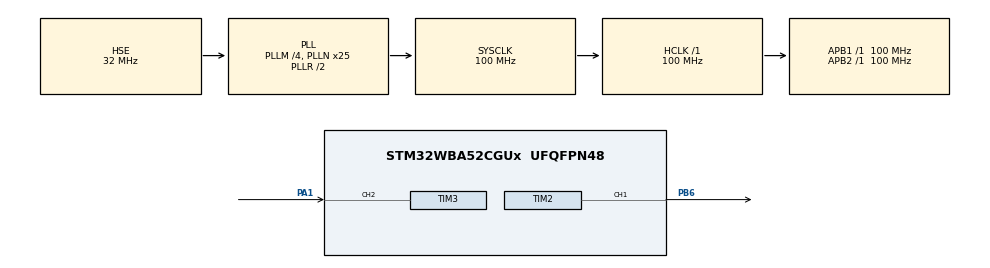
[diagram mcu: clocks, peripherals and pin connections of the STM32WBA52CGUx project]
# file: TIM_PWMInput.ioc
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CORTEX_M33_NS.userName=CORTEX_M33
Mcu.Family=STM32WBA
Mcu.Name=STM32WBA52CGUx
Mcu.Package=UFQFPN48
NVIC.PriorityGroup=NVIC_PRIORITYGROUP_4
OSC_IN.Mode=HSE-External-Oscillator
OSC_IN.Signal=RCC_OSC_IN
OSC_OUT.Mode=HSE-External-Oscillator
OSC_OUT.Signal=RCC_OSC_OUT
PA1.Signal=S_TIM3_CH2
PB6.Signal=S_TIM2_CH1
ProjectManager.HeapSize=0x200
ProjectManager.StackSize=0x400
ProjectManager.TargetToolchain=EWARM V9.20
RCC.ADCFreq_Value=100000000
RCC.AHB5CLKDivider=DIV4
RCC.AHBFreq_Value=100000000
RCC.APB1Freq_Value=100000000
RCC.APB1TimFreq_Value=100000000
RCC.APB2Freq_Value=100000000
RCC.APB2TimFreq_Value=100000000
RCC.CortexFreq_Value=100000000
RCC.HCLKFreq_Value=100000000
RCC.HSE_VALUE=32000000
RCC.HSI_VALUE=16000000
RCC.LSE_VALUE=32768
RCC.PLLFRACN=0
RCC.PLLM=4
RCC.PLLN=25
RCC.PLLSourceVirtual=RCC_PLLSOURCE_HSE
RCC.SYSCLKFreq_VALUE=100000000
RCC.SYSCLKSourceVirtual=RCC_SYSCLKSOURCE_PLLCLK
RCC.VCOOutputFreq_Value=200000000
SH.S_TIM2_CH1.0=TIM2_CH1,PWM Generation1 CH1
SH.S_TIM3_CH2.0=TIM3_CH2,Input_Capture2_from_TI2
SH.S_TIM3_CH2.1=TIM3_CH2,TriggerSource_TI2FP2
SH.S_TIM3_CH2.2=TIM3_CH2,Input_Capture1_from_TI2
TIM2.AutoReloadPreload=TIM_AUTORELOAD_PRELOAD_DISABLE
TIM2.Channel-PWM\ Generation1\ CH1=TIM_CHANNEL_1
TIM2.ClearInputSource=TIM_CLEARINPUTSOURCE_NONE
TIM2.ClockDivision=TIM_CLOCKDIVISION_DIV1
TIM2.CounterMode=TIM_COUNTERMODE_UP
TIM2.OC1Preload_PWM=ENABLE
TIM2.OCFastMode_PWM-PWM\ Generation1\ CH1=TIM_OCFAST_DISABLE
TIM2.OCMode_PWM-PWM\ Generation1\ CH1=TIM_OCMODE_PWM1
TIM2.OCPolarity_1=TIM_OCPOLARITY_HIGH
TIM2.Period=(SystemCoreClock/1)/aFrequency[0]
TIM2.Prescaler=uhPrescalerValue
TIM2.TIM_MasterOutputTrigger=TIM_TRGO_RESET
TIM2.TIM_MasterSlaveMode=TIM_MASTERSLAVEMODE_DISABLE
TIM3.AutoReloadPreload=TIM_AUTORELOAD_PRELOAD_DISABLE
TIM3.Channel-Input_Capture1_from_TI2=TIM_CHANNEL_1
TIM3.Channel-Input_Capture2_from_TI2=TIM_CHANNEL_2
TIM3.ClockDivision=TIM_CLOCKDIVISION_DIV1
TIM3.CounterMode=TIM_COUNTERMODE_UP
TIM3.ICFilter_CH2=0
TIM3.ICPolarity_CH1=TIM_INPUTCHANNELPOLARITY_FALLING
TIM3.ICPolarity_CH2=TIM_INPUTCHANNELPOLARITY_RISING
TIM3.ICPrescaler-Input_Capture1_from_TI2=TIM_ICPSC_DIV1
TIM3.ICPrescaler-Input_Capture2_from_TI2=TIM_ICPSC_DIV1
TIM3.ICSelection-Input_Capture1_from_TI2=TIM_ICSELECTION_INDIRECTTI
TIM3.ICSelection-Input_Capture2_from_TI2=TIM_ICSELECTION_DIRECTTI
TIM3.Period=0xFFFF
TIM3.Prescaler=0x0
TIM3.TIM_MasterOutputTrigger=TIM_TRGO_RESET
TIM3.TIM_MasterSlaveMode=TIM_MASTERSLAVEMODE_DISABLE
TIM3.TIM_SlaveMode=TIM_SLAVEMODE_RESET
VP_ICACHE_VS_ICACHE.Mode=DirectMappedCache
VP_PWR_VS_SECSignals.Mode=Security/Privilege
VP_TIM3_VS_ControllerModeReset.Mode=Reset Mode
board=custom

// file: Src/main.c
/* USER CODE BEGIN Header */
/**
  ******************************************************************************
  * @file    TIM/TIM_PWMInput/Src/main.c
  * @author  MCD Application Team
  * @brief   This example shows how to use the TIM peripheral to measure the
  *          frequency and duty cycle of an external signal.
  ******************************************************************************
  * @attention
  *
  * Copyright (c) 2022 STMicroelectronics.
  * All rights reserved.
  *
  * This software is licensed under terms that can be found in the LICENSE file
  * in the root directory of this software component.
  * If no LICENSE file comes with this software, it is provided AS-IS.
  *
  ******************************************************************************
  */
/* USER CODE END Header */
#include "main.h"

/* USER CODE BEGIN PD */
/* Number of frequencies */
#define TIM_FREQUENCIES_NB 6
#define TIM_DUTYCYCLE_NB 2
/* USER CODE END PD */

TIM_HandleTypeDef htim2;
TIM_HandleTypeDef htim3;

/* USER CODE BEGIN PV */

/* Captured Value */
__IO uint32_t            uwIC2Value = 0;
/* Duty Cycle Value */
__IO uint32_t            uwDutyCycle = 0;
/* Frequency Value */
__IO uint32_t            uwFrequency = 0;

/* Counter Prescaler value */
uint32_t uhPrescalerValue = 0;

static uint8_t iFrequency = 0;
/* Frequency index *//* Frequency table */
static uint32_t aFrequency[TIM_FREQUENCIES_NB] = {
  2000,   /*  2 kHz */
  2000,   /*  2 kHz */
  3000,   /*  3 kHz */
  3000,   /*  3 kHz */
  4000,   /*  4 kHz */
  4000,   /*  4 kHz */
};
/* Frequency index */

static uint8_t iDutyCycle = 0;
static uint32_t aDutyCycle[TIM_DUTYCYCLE_NB] = {
  2,   /*  50% */
  4,   /*  25% */
};

/* USER CODE END PV */

void SystemClock_Config(void);
static void MX_GPIO_Init(void);
static void MX_TIM3_Init(void);
static void MX_ICACHE_Init(void);
static void MX_TIM2_Init(void);

int main(void)
{
  /* USER CODE BEGIN 1 */

  /* STM32WBAxx HAL library initialization:
       - Systick timer is configured by default as source of time base, but user
             can eventually implement his proper time base source (a general purpose
             timer for example or other time source), keeping in mind that Time base
             duration should be kept 1ms since PPP_TIMEOUT_VALUEs are defined and
             handled in milliseconds basis.
       - Set NVIC Group Priority to 4
       - Low Level Initialization
     */

  /* USER CODE END 1 */

  /* MCU Configuration--------------------------------------------------------*/

  /* Reset of all peripherals, Initializes the Flash interface and the Systick. */
  HAL_Init();

  /* Configure the system clock */
  SystemClock_Config();

  /* USER CODE BEGIN SysInit */

  /* Configure LD3 */
  BSP_LED_Init(LD3);

  /* Configure User push-button in Interrupt mode */
  BSP_PB_Init(B1, BUTTON_MODE_EXTI);

  /* USER CODE END SysInit */

  /* Initialize all configured peripherals */
  MX_GPIO_Init();
  MX_TIM3_Init();
  MX_ICACHE_Init();
  MX_TIM2_Init();
  /* USER CODE BEGIN 2 */

 /* Start Input waveform generation */
  if (HAL_TIM_PWM_Start(&htim2, TIM_CHANNEL_1) != HAL_OK)
  {
    /* PWM Generation Error */
    Error_Handler();
  }

  /* Start the Input Capture in interrupt mode  */
  if (HAL_TIM_IC_Start_IT(&htim3, TIM_CHANNEL_2) != HAL_OK)
  {
    /* Starting Error */
    Error_Handler();
  }

  if (HAL_TIM_IC_Start_IT(&htim3, TIM_CHANNEL_1) != HAL_OK)
  {
    /* Starting Error */
    Error_Handler();
  }

  /* USER CODE END 2 */

  /* Infinite loop */
  while (1)
  {

  }
}

void SystemClock_Config(void)
{
  RCC_OscInitTypeDef RCC_OscInitStruct = {0};
  RCC_ClkInitTypeDef RCC_ClkInitStruct = {0};

  /** Configure the main internal regulator output voltage
  */
  if (HAL_PWREx_ControlVoltageScaling(PWR_REGULATOR_VOLTAGE_SCALE1) != HAL_OK)
  {
    Error_Handler();
  }

  /** Initializes the CPU, AHB and APB busses clocks
  */
  RCC_OscInitStruct.OscillatorType = RCC_OSCILLATORTYPE_HSE;
  RCC_OscInitStruct.HSEState = RCC_HSE_ON;
  RCC_OscInitStruct.HSEDiv = RCC_HSE_DIV1;
  RCC_OscInitStruct.PLL1.PLLState = RCC_PLL_ON;
  RCC_OscInitStruct.PLL1.PLLSource = RCC_PLLSOURCE_HSE;
  RCC_OscInitStruct.PLL1.PLLM = 4;
  RCC_OscInitStruct.PLL1.PLLN = 25;
  RCC_OscInitStruct.PLL1.PLLP = 2;
  RCC_OscInitStruct.PLL1.PLLQ = 2;
  RCC_OscInitStruct.PLL1.PLLR = 2;
  RCC_OscInitStruct.PLL1.PLLFractional = 0;
  if (HAL_RCC_OscConfig(&RCC_OscInitStruct) != HAL_OK)
  {
    Error_Handler();
  }

  /** Initializes the CPU, AHB and APB busses clocks
  */
  RCC_ClkInitStruct.ClockType = RCC_CLOCKTYPE_HCLK|RCC_CLOCKTYPE_SYSCLK
                              |RCC_CLOCKTYPE_PCLK1|RCC_CLOCKTYPE_PCLK2
                              |RCC_CLOCKTYPE_PCLK7|RCC_CLOCKTYPE_HCLK5;
  RCC_ClkInitStruct.SYSCLKSource = RCC_SYSCLKSOURCE_PLLCLK;
  RCC_ClkInitStruct.AHBCLKDivider = RCC_SYSCLK_DIV1;
  RCC_ClkInitStruct.APB1CLKDivider = RCC_HCLK_DIV1;
  RCC_ClkInitStruct.APB2CLKDivider = RCC_HCLK_DIV1;
  RCC_ClkInitStruct.APB7CLKDivider = RCC_HCLK_DIV1;
  RCC_ClkInitStruct.AHB5_PLL1_CLKDivider = RCC_SYSCLK_PLL1_DIV4;
  RCC_ClkInitStruct.AHB5_HSEHSI_CLKDivider = RCC_SYSCLK_HSEHSI_DIV1;

  if (HAL_RCC_ClockConfig(&RCC_ClkInitStruct, FLASH_LATENCY_3) != HAL_OK)
  {
    Error_Handler();
  }
}

static void MX_ICACHE_Init(void)
{

  /** Enable instruction cache in 1-way (direct mapped cache)
  */
  if (HAL_ICACHE_ConfigAssociativityMode(ICACHE_1WAY) != HAL_OK)
  {
    Error_Handler();
  }
  if (HAL_ICACHE_Enable() != HAL_OK)
  {
    Error_Handler();
  }

}

static void MX_TIM2_Init(void)
{

  TIM_MasterConfigTypeDef sMasterConfig = {0};
  TIM_OC_InitTypeDef sConfigOC = {0};

  htim2.Instance = TIM2;
  htim2.Init.Prescaler = uhPrescalerValue;
  htim2.Init.CounterMode = TIM_COUNTERMODE_UP;
  htim2.Init.Period = (SystemCoreClock/1)/aFrequency[0];
  htim2.Init.ClockDivision = TIM_CLOCKDIVISION_DIV1;
  htim2.Init.AutoReloadPreload = TIM_AUTORELOAD_PRELOAD_DISABLE;
  if (HAL_TIM_PWM_Init(&htim2) != HAL_OK)
  {
    Error_Handler();
  }
  sMasterConfig.MasterOutputTrigger = TIM_TRGO_RESET;
  sMasterConfig.MasterSlaveMode = TIM_MASTERSLAVEMODE_DISABLE;
  if (HAL_TIMEx_MasterConfigSynchronization(&htim2, &sMasterConfig) != HAL_OK)
  {
    Error_Handler();
  }
  sConfigOC.OCMode = TIM_OCMODE_PWM1;
  sConfigOC.Pulse = 0;
  sConfigOC.OCPolarity = TIM_OCPOLARITY_HIGH;
  sConfigOC.OCFastMode = TIM_OCFAST_DISABLE;
  if (HAL_TIM_PWM_ConfigChannel(&htim2, &sConfigOC, TIM_CHANNEL_1) != HAL_OK)
  {
    Error_Handler();
  }
  HAL_TIM_MspPostInit(&htim2);

}

static void MX_TIM3_Init(void)
{

  TIM_SlaveConfigTypeDef sSlaveConfig = {0};
  TIM_MasterConfigTypeDef sMasterConfig = {0};
  TIM_IC_InitTypeDef sConfigIC = {0};

  htim3.Instance = TIM3;
  htim3.Init.Prescaler = 0x0;
  htim3.Init.CounterMode = TIM_COUNTERMODE_UP;
  htim3.Init.Period = 0xFFFF;
  htim3.Init.ClockDivision = TIM_CLOCKDIVISION_DIV1;
  htim3.Init.AutoReloadPreload = TIM_AUTORELOAD_PRELOAD_DISABLE;
  if (HAL_TIM_Base_Init(&htim3) != HAL_OK)
  {
    Error_Handler();
  }
  if (HAL_TIM_IC_Init(&htim3) != HAL_OK)
  {
    Error_Handler();
  }
  sSlaveConfig.SlaveMode = TIM_SLAVEMODE_RESET;
  sSlaveConfig.InputTrigger = TIM_TS_TI2FP2;
  sSlaveConfig.TriggerPolarity = TIM_INPUTCHANNELPOLARITY_RISING;
  sSlaveConfig.TriggerFilter = 0;
  if (HAL_TIM_SlaveConfigSynchro(&htim3, &sSlaveConfig) != HAL_OK)
  {
    Error_Handler();
  }
  sMasterConfig.MasterOutputTrigger = TIM_TRGO_RESET;
  sMasterConfig.MasterSlaveMode = TIM_MASTERSLAVEMODE_DISABLE;
  if (HAL_TIMEx_MasterConfigSynchronization(&htim3, &sMasterConfig) != HAL_OK)
  {
    Error_Handler();
  }
  sConfigIC.ICPolarity = TIM_INPUTCHANNELPOLARITY_FALLING;
  sConfigIC.ICSelection = TIM_ICSELECTION_INDIRECTTI;
  sConfigIC.ICPrescaler = TIM_ICPSC_DIV1;
  sConfigIC.ICFilter = 0;
  if (HAL_TIM_IC_ConfigChannel(&htim3, &sConfigIC, TIM_CHANNEL_1) != HAL_OK)
  {
    Error_Handler();
  }
  sConfigIC.ICPolarity = TIM_INPUTCHANNELPOLARITY_RISING;
  sConfigIC.ICSelection = TIM_ICSELECTION_DIRECTTI;
  if (HAL_TIM_IC_ConfigChannel(&htim3, &sConfigIC, TIM_CHANNEL_2) != HAL_OK)
  {
    Error_Handler();
  }

}

static void MX_GPIO_Init(void)
{

  /* GPIO Ports Clock Enable */
  __HAL_RCC_GPIOA_CLK_ENABLE();
  __HAL_RCC_GPIOB_CLK_ENABLE();

}

/* USER CODE BEGIN 4 */

/**
  * @brief EXTI line detection callbacks
  * @param GPIO_Pin: Specifies the pins connected EXTI line
  * @retval None
  */
void UserButton_Callback()
{
    /* Set new PWM signal frequency and duty cycle*/
    iFrequency = (iFrequency + 1) % TIM_FREQUENCIES_NB;
    iDutyCycle = (iDutyCycle + 1) % TIM_DUTYCYCLE_NB;

    /* Set the auto-reload value to have the requested frequency */
    /* Frequency = TIM2CLK / (ARR + 1) = SystemCoreClock / (ARR + 1)  */
    LL_TIM_SetAutoReload(TIM2, __LL_TIM_CALC_ARR(SystemCoreClock/1, LL_TIM_GetPrescaler(TIM2), aFrequency[iFrequency]));

    /* Set  duty cycle */
    LL_TIM_OC_SetCompareCH1(TIM2, (LL_TIM_GetAutoReload(TIM2) / aDutyCycle[iDutyCycle]));

}

/**
  * @brief  Input Capture callback in non blocking mode
  * @param  htim : TIM IC handle
  * @retval None
  */
void TimerCaptureCompare_Ch2_Callback()
{
  /* Get the Input Capture value */
  uwIC2Value = LL_TIM_IC_GetCaptureCH2(TIM3);

  if (uwIC2Value != 0)
  {
    /* Duty cycle computation */
    uwDutyCycle = (LL_TIM_IC_GetCaptureCH1(TIM3) * 100) / uwIC2Value;

    /* uwFrequency computation
    TIM3 freq  = SystemCoreClock */
    uwFrequency = SystemCoreClock  / (1*uwIC2Value);
  }
  else
  {
    uwDutyCycle = 0;
    uwFrequency = 0;
  }
}

/* USER CODE END 4 */

void Error_Handler(void)
{
  /* USER CODE BEGIN Error_Handler_Debug */
  /* User can add his own implementation to report the HAL error return state */
  /* Turn LD3 on */
  BSP_LED_On(LD3);
  while (1)
  {
  }
  /* USER CODE END Error_Handler_Debug */
}
